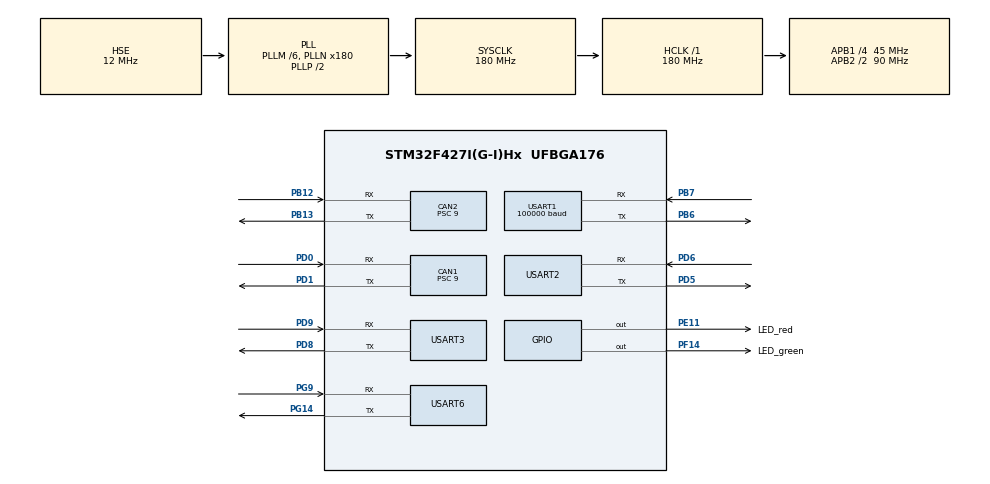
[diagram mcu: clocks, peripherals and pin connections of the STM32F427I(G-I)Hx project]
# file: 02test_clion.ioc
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CAN1.BS1=CAN_BS1_2TQ
CAN1.BS2=CAN_BS2_2TQ
CAN1.CalculateBaudRate=1000000
CAN1.CalculateTimeBit=1000
CAN1.CalculateTimeQuantum=200.0
CAN1.Prescaler=9
CAN2.BS1=CAN_BS1_2TQ
CAN2.BS2=CAN_BS2_2TQ
CAN2.CalculateBaudRate=1000000
CAN2.CalculateTimeBit=1000
CAN2.CalculateTimeQuantum=200.0
CAN2.Prescaler=9
Dma.Request0=USART2_RX
Dma.Request1=USART2_TX
Dma.Request2=USART6_RX
Dma.USART2_RX.0.Direction=DMA_PERIPH_TO_MEMORY
Dma.USART2_RX.0.FIFOMode=DMA_FIFOMODE_DISABLE
Dma.USART2_RX.0.Instance=DMA1_Stream5
Dma.USART2_RX.0.MemDataAlignment=DMA_MDATAALIGN_BYTE
Dma.USART2_RX.0.MemInc=DMA_MINC_ENABLE
Dma.USART2_RX.0.Mode=DMA_NORMAL
Dma.USART2_RX.0.PeriphDataAlignment=DMA_PDATAALIGN_BYTE
Dma.USART2_RX.0.PeriphInc=DMA_PINC_DISABLE
Dma.USART2_RX.0.Priority=DMA_PRIORITY_LOW
Dma.USART2_TX.1.Direction=DMA_MEMORY_TO_PERIPH
Dma.USART2_TX.1.FIFOMode=DMA_FIFOMODE_DISABLE
Dma.USART2_TX.1.Instance=DMA1_Stream6
Dma.USART2_TX.1.MemDataAlignment=DMA_MDATAALIGN_BYTE
Dma.USART2_TX.1.MemInc=DMA_MINC_ENABLE
Dma.USART2_TX.1.Mode=DMA_NORMAL
Dma.USART2_TX.1.PeriphDataAlignment=DMA_PDATAALIGN_BYTE
Dma.USART2_TX.1.PeriphInc=DMA_PINC_DISABLE
Dma.USART2_TX.1.Priority=DMA_PRIORITY_LOW
Dma.USART6_RX.2.Direction=DMA_PERIPH_TO_MEMORY
Dma.USART6_RX.2.FIFOMode=DMA_FIFOMODE_DISABLE
Dma.USART6_RX.2.Instance=DMA2_Stream1
Dma.USART6_RX.2.MemDataAlignment=DMA_MDATAALIGN_BYTE
Dma.USART6_RX.2.MemInc=DMA_MINC_ENABLE
Dma.USART6_RX.2.Mode=DMA_NORMAL
Dma.USART6_RX.2.PeriphDataAlignment=DMA_PDATAALIGN_BYTE
Dma.USART6_RX.2.PeriphInc=DMA_PINC_DISABLE
Dma.USART6_RX.2.Priority=DMA_PRIORITY_LOW
Mcu.Family=STM32F4
Mcu.Name=STM32F427I(G-I)Hx
Mcu.Package=UFBGA176
NVIC.CAN1_RX0_IRQn=true\:0\:0\:false\:false\:true\:true\:true\:true
NVIC.DMA1_Stream5_IRQn=true\:0\:0\:false\:false\:true\:false\:true\:true
NVIC.DMA1_Stream6_IRQn=true\:0\:0\:false\:false\:true\:false\:true\:true
NVIC.DMA2_Stream1_IRQn=true\:0\:0\:false\:false\:true\:false\:true\:true
NVIC.PriorityGroup=NVIC_PRIORITYGROUP_4
NVIC.USART1_IRQn=true\:0\:0\:false\:false\:true\:true\:true\:true
NVIC.USART2_IRQn=true\:0\:0\:false\:false\:true\:true\:true\:true
NVIC.USART3_IRQn=true\:0\:0\:false\:false\:true\:true\:true\:true
NVIC.USART6_IRQn=true\:0\:0\:false\:false\:true\:true\:true\:true
PA13.Mode=Serial_Wire
PA13.Signal=SYS_JTMS-SWDIO
PA14.Mode=Serial_Wire
PA14.Signal=SYS_JTCK-SWCLK
PB12.Mode=CAN_Activate
PB12.Signal=CAN2_RX
PB13.Mode=CAN_Activate
PB13.Signal=CAN2_TX
PB6.Mode=Asynchronous
PB6.Signal=USART1_TX
PB7.Mode=Asynchronous
PB7.Signal=USART1_RX
PD0.Mode=CAN_Activate
PD0.Signal=CAN1_RX
PD1.Mode=CAN_Activate
PD1.Signal=CAN1_TX
PD5.Mode=Asynchronous
PD5.Signal=USART2_TX
PD6.Mode=Asynchronous
PD6.Signal=USART2_RX
PD8.Mode=Asynchronous
PD8.Signal=USART3_TX
PD9.Mode=Asynchronous
PD9.Signal=USART3_RX
PE11.GPIO_Label=LED_red
PE11.GPIO_PuPd=GPIO_PULLUP
PE11.PinState=GPIO_PIN_SET
PE11.Signal=GPIO_Output
PF14.GPIO_Label=LED_green
PF14.GPIO_PuPd=GPIO_PULLUP
PF14.PinState=GPIO_PIN_SET
PF14.Signal=GPIO_Output
PG14.Mode=Asynchronous
PG14.Signal=USART6_TX
PG9.Mode=Asynchronous
PG9.Signal=USART6_RX
PH0/OSC_IN.Mode=HSE-External-Oscillator
PH0/OSC_IN.Signal=RCC_OSC_IN
PH1/OSC_OUT.Mode=HSE-External-Oscillator
PH1/OSC_OUT.Signal=RCC_OSC_OUT
ProjectManager.HeapSize=0x200
ProjectManager.StackSize=0x400
ProjectManager.TargetToolchain=CMake
RCC.48MHZClocksFreq_Value=90000000
RCC.AHBFreq_Value=180000000
RCC.APB1CLKDivider=RCC_HCLK_DIV4
RCC.APB1Freq_Value=45000000
RCC.APB1TimFreq_Value=90000000
RCC.APB2CLKDivider=RCC_HCLK_DIV2
RCC.APB2Freq_Value=90000000
RCC.APB2TimFreq_Value=180000000
RCC.CortexFreq_Value=180000000
RCC.HCLKFreq_Value=180000000
RCC.HSE_VALUE=12000000
RCC.HSI_VALUE=16000000
RCC.LSE_VALUE=32768
RCC.PLLM=6
RCC.PLLN=180
RCC.PLLSourceVirtual=RCC_PLLSOURCE_HSE
RCC.SYSCLKFreq_VALUE=180000000
RCC.SYSCLKSource=RCC_SYSCLKSOURCE_PLLCLK
RCC.VCOOutputFreq_Value=360000000
USART1.BaudRate=100000
USART1.VirtualMode=VM_ASYNC
USART2.VirtualMode=VM_ASYNC
USART3.VirtualMode=VM_ASYNC
USART6.VirtualMode=VM_ASYNC
board=custom

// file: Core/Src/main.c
/* USER CODE BEGIN Header */
/**
  ******************************************************************************
  * @file           : main.c
  * @brief          : Main program body
  ******************************************************************************
  * @attention
  *
  * Copyright (c) 2026 STMicroelectronics.
  * All rights reserved.
  *
  * This software is licensed under terms that can be found in the LICENSE file
  * in the root directory of this software component.
  * If no LICENSE file comes with this software, it is provided AS-IS.
  *
  ******************************************************************************
  */
/* USER CODE END Header */
#include "main.h"
#include "can.h"
#include "dma.h"
#include "usart.h"
#include "gpio.h"

/* USER CODE BEGIN Includes */
#include "Task.h"

/* USER CODE END Includes */

void SystemClock_Config(void);

int main(void)
{

  /* MCU Configuration--------------------------------------------------------*/

  /* Reset of all peripherals, Initializes the Flash interface and the Systick. */
  HAL_Init();

  /* Configure the system clock */
  SystemClock_Config();

  /* Initialize all configured peripherals */
  MX_GPIO_Init();
  MX_DMA_Init();
  MX_USART2_UART_Init();
  MX_CAN1_Init();
  MX_CAN2_Init();
  MX_USART1_UART_Init();
  MX_USART3_UART_Init();
  MX_USART6_UART_Init();
  /* USER CODE BEGIN 2 */

  Task_Init();

  /* USER CODE END 2 */

  /* Infinite loop */
  /* USER CODE BEGIN WHILE */
  while (1)
  {
    Task_Loop();
    /* USER CODE END WHILE */

  }
}

void SystemClock_Config(void)
{
  RCC_OscInitTypeDef RCC_OscInitStruct = {0};
  RCC_ClkInitTypeDef RCC_ClkInitStruct = {0};

  /** Configure the main internal regulator output voltage
  */
  __HAL_RCC_PWR_CLK_ENABLE();
  __HAL_PWR_VOLTAGESCALING_CONFIG(PWR_REGULATOR_VOLTAGE_SCALE1);

  /** Initializes the RCC Oscillators according to the specified parameters
  * in the RCC_OscInitTypeDef structure.
  */
  RCC_OscInitStruct.OscillatorType = RCC_OSCILLATORTYPE_HSE;
  RCC_OscInitStruct.HSEState = RCC_HSE_ON;
  RCC_OscInitStruct.PLL.PLLState = RCC_PLL_ON;
  RCC_OscInitStruct.PLL.PLLSource = RCC_PLLSOURCE_HSE;
  RCC_OscInitStruct.PLL.PLLM = 6;
  RCC_OscInitStruct.PLL.PLLN = 180;
  RCC_OscInitStruct.PLL.PLLP = RCC_PLLP_DIV2;
  RCC_OscInitStruct.PLL.PLLQ = 4;
  if (HAL_RCC_OscConfig(&RCC_OscInitStruct) != HAL_OK)
  {
    Error_Handler();
  }

  /** Activate the Over-Drive mode
  */
  if (HAL_PWREx_EnableOverDrive() != HAL_OK)
  {
    Error_Handler();
  }

  /** Initializes the CPU, AHB and APB buses clocks
  */
  RCC_ClkInitStruct.ClockType = RCC_CLOCKTYPE_HCLK|RCC_CLOCKTYPE_SYSCLK
                              |RCC_CLOCKTYPE_PCLK1|RCC_CLOCKTYPE_PCLK2;
  RCC_ClkInitStruct.SYSCLKSource = RCC_SYSCLKSOURCE_PLLCLK;
  RCC_ClkInitStruct.AHBCLKDivider = RCC_SYSCLK_DIV1;
  RCC_ClkInitStruct.APB1CLKDivider = RCC_HCLK_DIV4;
  RCC_ClkInitStruct.APB2CLKDivider = RCC_HCLK_DIV2;

  if (HAL_RCC_ClockConfig(&RCC_ClkInitStruct, FLASH_LATENCY_5) != HAL_OK)
  {
    Error_Handler();
  }
}

void Error_Handler(void)
{
  __disable_irq();
  while (1)
  {
  }
}
